# CEC1712H_N2_SX register map
Vendor: Microchip
Registers are 32-bit, read-write, reset 0x0 unless marked. A register's access mark holds for its fields unless they carry their own. Addresses are absolute, and some are shared; only a register's first bit layout is shown; [hi:lo] are bit positions; {n}, {i} and the like mark numbered series; 'fields as' and 'values as' point back to an identical list.

## EC_REG_BANK
0x4000FC04 AHB_ERR_ADDR
0x4000FC14 AHB_ERR_CTRL 8-bit
0x4000FC18 INTR_CTRL reset 0x1
0x4000FC1C ETM_CTRL
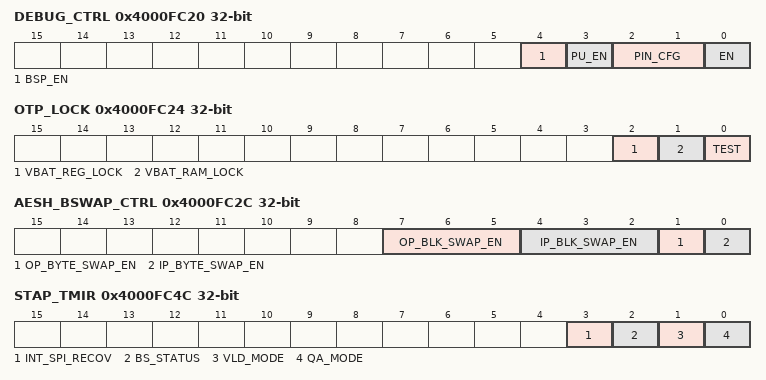
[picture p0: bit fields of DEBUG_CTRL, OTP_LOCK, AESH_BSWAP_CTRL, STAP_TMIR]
0x4000FC20 DEBUG_CTRL
  [4] BSP_EN — This bit sets the boundary scan tap controller accessibility from JTAG port. 1= Boundary scan tap controller accessibile through JTAG Port. 0= Boundary scan tap controller not accessibile through JTAG Port.
  [3] PU_EN — If this bit is set to '1b' internal pull-up resistors are automatically enabled on the appropriate debugging port wires whenever the debug port is enabled (the DEBUG_EN bit in this register is '1b' and the JTAG_RST# pin is high). The setting of DEBUG_PIN_CFG determines which pins have pull-ups enabled when the debug port is enabled.
  [2:1] PIN_CFG — This field determines which pins are affected by the TRST# debug enable pin. 3=Reserved 2=The pins associated with the JTAG TCK and TMS switch to the debug interface when TRST# is de-asserted high. The pins associated with TDI and TDO remain controlled by the associated GPIO. This setting should be used when the ARM Serial Wire Debug (SWD) is required for debugging and the Serial Wire Viewer is not required 1=The pins associated with the JTAG TCK, TMS and TDO switch to the debug interface when TRST# is de-asserted high. The pin associated with TDI remains controlled by the associated GPIO. This setting should be used when the ARM Serial Wire Debug (SWD) and Serial Wire Viewer (SWV) are both required for debugging 0=All four pins associated with JTAG (TCK, TMS, TDI and TDO) switch to the debug interface when TRST# is de-asserted high. This setting should be used when the JTAG TAP controller is required for debugging.
    2=JTAG_TCK_TMS (2=The pins associated with the JTAG TCK and TMS switch to the debug interface when TRST# is de-asserted high. The pins associated with TDI and TDO remain controlled by the associated GPIO. This setting should be used when the ARM Serial. Wire Debug (SWD) is required for debugging and the Serial Wire Viewer is not required); 1=JTAG_TCK_TMS_TDO (1=The pins associated with the JTAG TCK, TMS and TDO switch to the debug interface when TRST# is de-asserted high. The pin associated with TDI remains controlled by the associated GPIO. This setting should be used when the ARM Serial Wire Debug (SWD) and Serial Wire Viewer (SWV) are both required for debugging); 0=JTAG_TCK_TMS_TDO_TDI (0=All four pins associated with JTAG (TCK, TMS, TDI and TDO) switch to the debug interface when TRST# is de-asserted high. This setting should be used when the JTAG TAP controller is required for debugging.)
  [0] EN — DEBUG_EN (JTAG_EN) This bit enables the JTAG/SWD debug port. 0= JTAG/SWD port disabled. JTAG/SWD cannot be enabled (i.e., the TRST# pin is ignored and the JTAG signals remain in their non-JTAG state). 1= JTAG/SWD port enabled. A high on TRST# enables JTAG or SWD, as determined by SWD_EN.
0x4000FC24 OTP_LOCK
  [2] VBAT_REG_LOCK — VBAT REG LOCK. 0 = Not Locked. 1 = Locked.
  [1] VBAT_RAM_LOCK — VBAT RAM LOCK bit. 0 = Not Locked. 1 = Locked.
  [0] TEST
0x4000FC28 WDT_CNT
0x4000FC2C AESH_BSWAP_CTRL
  [7:5] OP_BLK_SWAP_EN — Used to enable word swap on a DWORD during AHB write from AES / HASH block 4=Swap 32-bit doublewords in 128-byte blocks 3=Swap doublewords in 64-byte blocks. Useful for SHA-256. Bus references issued in the order 0x3C, 0x38, 0x34, 0x30, 0x2C, 0x28, 0x24, 0x20, 0x1C, 0x18, 0x14, 0x10, 0xC, 0x8, 0x4, 0x0,... 2=Swap doublewords in 16-byte blocks. Useful for AES. Bus references issued in the order 0xC, 0x8, 0x4, 0x0, 0x1C, 0x18,... 1=Swap doublewords in 8-byte blocks. Useful for SHA-512, which works on 64-bit words. Bus references issued in the order 0x4, 0x0, 0xC, 0x8, ... 0=Disable.
    4=SWAP_128_BYTE_BLOCK (4=Swap 32-bit doublewords in 128-byte blocks); 3=SWAP_64_BYTE_BLOCK (3=Swap doublewords in 64-byte blocks. Useful for SHA-256. Bus references issued in the order 0x3C, 0x38, 0x34, 0x30, 0x2C, 0x28, 0x24, 0x20, 0x1C, 0x18, 0x14, 0x10, 0xC, 0x8, 0x4, 0x0,...); 2=SWAP_16_BYTE_BLOCK (2=Swap doublewords in 16-byte blocks. Useful for AES. Bus references issued in the order 0xC, 0x8, 0x4, 0x0, 0x1C, 0x18,...); 1=SWAP_8_BYTE_BLOCK (1=Swap doublewords in 8-byte blocks. Useful for SHA-512, which works on 64-bit words. Bus references issued in the order 0x4, 0x0, 0xC, 0x8, ...); 0=DIS (0=Disable.)
  [4:2] IP_BLK_SWAP_EN — Used to enable word swap on a DWORD during AHB read from AES / HASH block 4=Swap 32-bit doublewords in 128-byte blocks 3=Swap doublewords in 64-byte blocks. Useful for SHA-256. Bus references issued in the order 0x3C, 0x38, 0x34, 0x30, 0x2C, 0x28, 0x24, 0x20, 0x1C, 0x18, 0x14, 0x10, 0xC, 0x8, 0x4, 0x0,... 2=Swap doublewords in 16-byte blocks. Useful for AES. Bus references issued in the order 0xC, 0x8, 0x4, 0x0, 0x1C, 0x18,... 1=Swap doublewords in 8-byte blocks. Useful for SHA-512, which works on 64-bit words. Bus references issued in the order 0x4, 0x0, 0xC, 0x8, ... 0=Disable.
    values as OP_BLK_SWAP_EN
  [1] OP_BYTE_SWAP_EN — Used to enable byte swap on a DWORD during AHB write from AES / HASH block: 1=Enable; 0=Disable.
  [0] IP_BYTE_SWAP_EN — Used to enable byte swap on a DWORD during AHB read from AES / HASH block: 1=Enable; 0=Disable.
0x4000FC40 PECI_DIS
  [0] P_DIS — When this bit is asserted ('1'), it disables the PECI pads to reduce leakage.
0x4000FC4C STAP_TMIR ro
  [3] INT_SPI_RECOV — This register bit tells BOOT ROM that SPI FLASH Recovery Mode is entered.
  [2] BS_STATUS — This register bit tells BOOT ROM about the Boundary Scan Status.
  [1] VLD_MODE — This is the mirror of the Validation MODE (bit 1) of Boot Control Register. This register bit tells BOOT ROM to enter the Validation mode.
  [0] QA_MODE — This is the mirror of the QA_MODE (bit 0) of Boot Control Register. This register bit tells BOOT ROM to enter the QA mode.
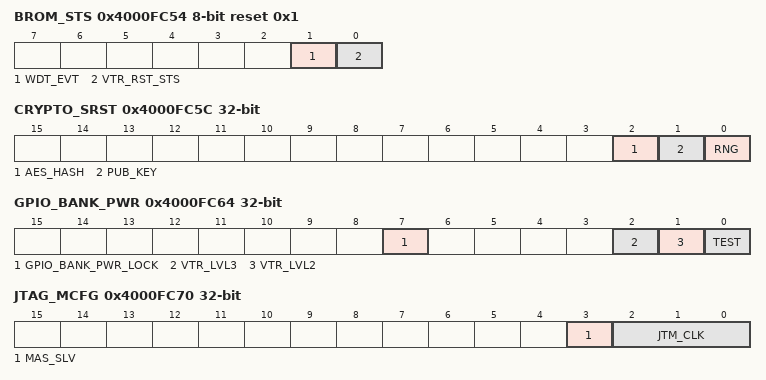
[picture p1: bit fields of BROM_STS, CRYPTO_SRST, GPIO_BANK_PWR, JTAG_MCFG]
0x4000FC54 BROM_STS 8-bit reset 0x1
  [1] WDT_EVT — This bit contains the WDT Event Status for BOOT ROM usage. 1= WDT event occured. 0= WDT event did not occured. This registe is R/W1C (read / write 1 to clear).
  [0] VTR_RST_STS — This bit contains the RESET_SYS Status for BOOT ROM usage. 1= RESET_SYS event occured. 0= RESET_SYS event did not occured. This registe is R/W1C (read / write 1 to clear).
0x4000FC5C CRYPTO_SRST
  [2] AES_HASH — When this bit is asserted ('1'), the AES and Hash blocks are reset.
  [1] PUB_KEY — When this bit is asserted ('1'), the Public Key block is reset.
  [0] RNG — When this bit is asserted ('1'), the Random Number Generator block is reset.
0x4000FC64 GPIO_BANK_PWR
  [7] GPIO_BANK_PWR_LOCK — GPIO Bank Power Lock. 0: VTR_LEVEL bits[2:0] and GPIO Bank Power Lock bit are R/W. 1 = VTR_LEVEL bits[2:0] and GPIO Bank Power Lock bit are Read Only.
  [2] VTR_LVL3 — Voltage value on VTR3. This bit is set by hardware after a VTR Power On Reset, but may be overridden by software. It must be set by software if the VTR power rail is not active when RESET_SYS is de-asserted. Write access is determined by bit 7. 1=VTR3 is powered by 1.8V. 0=VTR3 is powered by 3.3V.
  [1] VTR_LVL2 — Voltage value on VTR2. This bit is set by Firmware after a VTR Power On Reset. It must be set by software if the VTR power rail is not active when RESET_SYS is de-asserted. Write access is determined by bit 7. 1=VTR2 is powered by 1.8V. 0=VTR2 is powered by 3.3V.
  [0] TEST — This bit must be programmed to 0h for proper operation of the device.
0x4000FC70 JTAG_MCFG
  [3] MAS_SLV — This bit controls the direction of the JTAG port. 1=The JTAG Port is configured as a Master. 0=The JTAG Port is configures as a Slave.
  [2:0] JTM_CLK — This field determines the JTAG Master clock rate, derived from the 48MHz master clock. 7=375KHz; 6=750KHz; 5=1.5Mhz; 4=3Mhz; 3=6Mhz; 2=12Mhz; 1=24MHz; 0=Reserved.
    7=JTM_CLK_375KHz (7=375KHz); 6=JTM_CLK_750KHz (6=750KHz); 5=JTM_CLK_1MHz (5=1.5Mhz); 4=JTM_CLK_3Mhz (4=3Mhz); 3=JTM_CLK_6Mhz (3=6Mhz); 2=JTM_CLK_12Mhz (2=12Mhz); 1=JTM_CLK_24MHz (1=24MHz)
0x4000FC74 JTAG_MSTS ro
  [0] JTM_DONE — This bit is set to '1b' when the JTAG Master Command Register is written. It becomes '0b' when shifting has completed. Software can poll this bit to determine when a command has completed and it is therefore safe to remove the data in the JTAG Master TDO. Register and load new data into the JTAG Master TMS Register and the JTAG Master TDI Register.
0x4000FC78 JTAG_MTDO
  [31:0] JTM_TDO — When the JTAG Master Command Register is written, from 1 to 32 bits are shifted into this register, starting with bit 0, from the JTAG_TDO pin. Shifting is at the rate determined by the JTM_CLK field in the JTAG Master Configuration Register.
0x4000FC7C JTAG_MTDI
  [31:0] JTM_TDI — When the JTAG Master Command Register is written, from 1 to 32 bits are shifted out of this register, starting with bit 0, onto the JTAG_TDI pin. Shifting is at the rate determined by the JTM_CLK field in the JTAG Master Configuration Register.
0x4000FC80 JTAG_MTMS
  [31:0] JTM_TMS — When the JTAG Master Command Register is written, from 1 to 32 bits are shifted out of this register, starting with bit 0, onto the JTAG_TMS pin. Shifting is at the rate determined by the JTM_CLK field in the JTAG Master Configuration Register.
0x4000FC84 JTAG_MCMD
  [4:0] JTM_COUNT — If the JTAG Port is configured as a Master, writing this register starts clocking and shifting on the JTAG port. The JTAG. Master port will shift JTM_COUNT+1 times, so writing a '0h' will shift 1 bit, and writing '31h' will shift 32 bits. The signal JTAG_CLK will cycle JTM_COUNT+1 times. The contents of the JTAG Master TMS Register and the JTAG Master TDI Register will be shifted out on the falling edge of JTAG_CLK and the.JTAG Master TDO Register will get shifted in on the rising edge of JTAG_CLK. If the JTAG Port is configured as a Slave, writing this register has no effect.
{0x4000FD80+4i} FW_SCR{i} (i=0..3)
  [31:0] SCR{i} — This field has no functionality other than storage. This register is aliased to ESPI Config Scratch Register.
